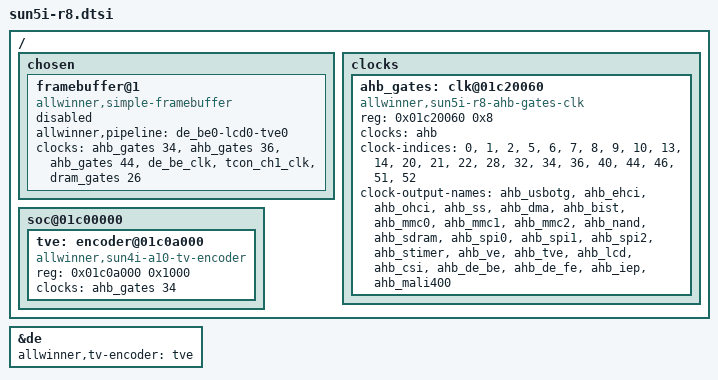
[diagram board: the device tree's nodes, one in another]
/*
 * Copyright 2015 Free Electrons
 * Copyright 2015 NextThing Co
 *
 * Maxime Ripard <maxime.ripard@free-electrons.com>
 *
 * This file is dual-licensed: you can use it either under the terms
 * of the GPL or the X11 license, at your option. Note that this dual
 * licensing only applies to this file, and not this project as a
 * whole.
 *
 *  a) This file is free software; you can redistribute it and/or
 *     modify it under the terms of the GNU General Public License as
 *     published by the Free Software Foundation; either version 2 of the
 *     License, or (at your option) any later version.
 *
 *     This file is distributed in the hope that it will be useful,
 *     but WITHOUT ANY WARRANTY; without even the implied warranty of
 *     MERCHANTABILITY or FITNESS FOR A PARTICULAR PURPOSE.  See the
 *     GNU General Public License for more details.
 *
 * Or, alternatively,
 *
 *  b) Permission is hereby granted, free of charge, to any person
 *     obtaining a copy of this software and associated documentation
 *     files (the "Software"), to deal in the Software without
 *     restriction, including without limitation the rights to use,
 *     copy, modify, merge, publish, distribute, sublicense, and/or
 *     sell copies of the Software, and to permit persons to whom the
 *     Software is furnished to do so, subject to the following
 *     conditions:
 *
 *     The above copyright notice and this permission notice shall be
 *     included in all copies or substantial portions of the Software.
 *
 *     THE SOFTWARE IS PROVIDED "AS IS", WITHOUT WARRANTY OF ANY KIND,
 *     EXPRESS OR IMPLIED, INCLUDING BUT NOT LIMITED TO THE WARRANTIES
 *     OF MERCHANTABILITY, FITNESS FOR A PARTICULAR PURPOSE AND
 *     NONINFRINGEMENT. IN NO EVENT SHALL THE AUTHORS OR COPYRIGHT
 *     HOLDERS BE LIABLE FOR ANY CLAIM, DAMAGES OR OTHER LIABILITY,
 *     WHETHER IN AN ACTION OF CONTRACT, TORT OR OTHERWISE, ARISING
 *     FROM, OUT OF OR IN CONNECTION WITH THE SOFTWARE OR THE USE OR
 *     OTHER DEALINGS IN THE SOFTWARE.
 */

#include "sun5i-a13.dtsi"

/ {
	chosen {
		framebuffer@1 {
			compatible = "allwinner,simple-framebuffer",
				     "simple-framebuffer";
			allwinner,pipeline = "de_be0-lcd0-tve0";
			clocks = <&ahb_gates 34>, <&ahb_gates 36>,
				 <&ahb_gates 44>, <&de_be_clk>,
				 <&tcon_ch1_clk>, <&dram_gates 26>;
			status = "disabled";
		};
	};

	clocks {
		ahb_gates: clk@01c20060 {
			#clock-cells = <1>;
			compatible = "allwinner,sun5i-r8-ahb-gates-clk";
			reg = <0x01c20060 0x8>;
			clocks = <&ahb>;
			clock-indices = <0>, <1>,
					<2>, <5>, <6>,
					<7>, <8>, <9>,
					<10>, <13>,
					<14>, <20>,
					<21>, <22>,
					<28>, <32>, <34>,
					<36>, <40>, <44>,
					<46>, <51>,
					<52>;
			clock-output-names = "ahb_usbotg", "ahb_ehci",
					     "ahb_ohci", "ahb_ss", "ahb_dma",
					     "ahb_bist", "ahb_mmc0", "ahb_mmc1",
					     "ahb_mmc2", "ahb_nand",
					     "ahb_sdram", "ahb_spi0",
					     "ahb_spi1", "ahb_spi2",
					     "ahb_stimer", "ahb_ve", "ahb_tve",
					     "ahb_lcd", "ahb_csi", "ahb_de_be",
					     "ahb_de_fe", "ahb_iep",
					     "ahb_mali400";
		};
	};

	soc@01c00000 {
		tve: encoder@01c0a000 {
			compatible = "allwinner,sun4i-a10-tv-encoder";
			reg = <0x01c0a000 0x1000>;
			clocks = <&ahb_gates 34>;
		};
	};
};

&de {
	allwinner,tv-encoder = <&tve>;
};
